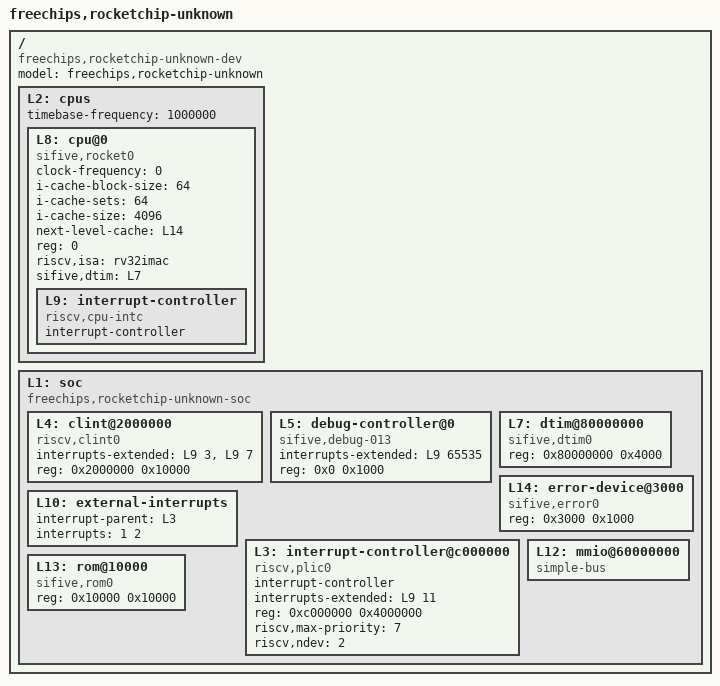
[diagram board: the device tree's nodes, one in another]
/dts-v1/;

/ {
	#address-cells = <1>;
	#size-cells = <1>;
	compatible = "freechips,rocketchip-unknown-dev";
	model = "freechips,rocketchip-unknown";
	L2: cpus {
		#address-cells = <1>;
		#size-cells = <0>;
		timebase-frequency = <1000000>;
		L8: cpu@0 {
			clock-frequency = <0>;
			compatible = "sifive,rocket0", "riscv";
			device_type = "cpu";
			i-cache-block-size = <64>;
			i-cache-sets = <64>;
			i-cache-size = <4096>;
			next-level-cache = <&L14>;
			reg = <0>;
			riscv,isa = "rv32imac";
			sifive,dtim = <&L7>;
			status = "okay";
			L9: interrupt-controller {
				#interrupt-cells = <1>;
				compatible = "riscv,cpu-intc";
				interrupt-controller;
			};
		};
	};
	L1: soc {
		#address-cells = <1>;
		#size-cells = <1>;
		compatible = "freechips,rocketchip-unknown-soc", "simple-bus";
		ranges;
		L4: clint@2000000 {
			compatible = "riscv,clint0";
			interrupts-extended = <&L9 3 &L9 7>;
			reg = <0x2000000 0x10000>;
			reg-names = "control";
		};
		L5: debug-controller@0 {
			compatible = "sifive,debug-013", "riscv,debug-013";
			interrupts-extended = <&L9 65535>;
			reg = <0x0 0x1000>;
			reg-names = "control";
		};
		L7: dtim@80000000 {
			compatible = "sifive,dtim0";
			reg = <0x80000000 0x4000>;
			reg-names = "mem";
		};
		L14: error-device@3000 {
			compatible = "sifive,error0";
			reg = <0x3000 0x1000>;
			reg-names = "mem";
		};
		L10: external-interrupts {
			interrupt-parent = <&L3>;
			interrupts = <1 2>;
		};
		L3: interrupt-controller@c000000 {
			#interrupt-cells = <1>;
			compatible = "riscv,plic0";
			interrupt-controller;
			interrupts-extended = <&L9 11>;
			reg = <0xc000000 0x4000000>;
			reg-names = "control";
			riscv,max-priority = <7>;
			riscv,ndev = <2>;
		};
		L12: mmio@60000000 {
			#address-cells = <1>;
			#size-cells = <1>;
			compatible = "simple-bus";
			ranges = <0x60000000 0x60000000 0x20000000>;
		};
		L13: rom@10000 {
			compatible = "sifive,rom0";
			reg = <0x10000 0x10000>;
			reg-names = "mem";
		};
	};
};
